# ESP32-C2 register map
Vendor: ESPRESSIF SYSTEMS (SHANGHAI) CO., LTD.; Series: ESP32 C-Series; File version: 11
CPU: RV32IMC r0p0, little endian, no MPU, no FPU, 0 interrupt priority bits
Address unit: 32 bits
Registers are 32-bit, read-write, reset 0x0 unless marked. A register's access mark holds for its fields unless they carry their own. Offsets are from the block's base; [hi:lo] are bit positions; {n}, {i} and the like mark numbered series.

## EFUSE — eFuse Controller
Base 0x60008800
0x00 PGM_DATA0 — Register 0 that stores data to be programmed.
  [31:0] PGM_DATA_0 — The content of the 0th 32-bit data to be programmed.
0x04 PGM_DATA1 — Register 1 that stores data to be programmed.
  [31:0] PGM_DATA_1 — The content of the 1st 32-bit data to be programmed.
0x08 PGM_DATA2 — Register 2 that stores data to be programmed.
  [31:0] PGM_DATA_2 — The content of the 2nd 32-bit data to be programmed.
0x0C PGM_DATA3 — Register 3 that stores data to be programmed.
  [31:0] PGM_DATA_3 — The content of the 3rd 32-bit data to be programmed.
{0x0+4i} PGM_DATA{i} (i=4..7) — Register {i} that stores data to be programmed.
  [31:0] PGM_DATA_{i} — The content of the {i}th 32-bit data to be programmed.
0x20 PGM_CHECK_VALUE0 — Register 0 that stores the RS code to be programmed.
  [31:0] PGM_RS_DATA_0 — The content of the 0th 32-bit RS code to be programmed.
0x24 PGM_CHECK_VALUE1 — Register 1 that stores the RS code to be programmed.
  [31:0] PGM_RS_DATA_1 — The content of the 1st 32-bit RS code to be programmed.
0x28 PGM_CHECK_VALUE2 — Register 2 that stores the RS code to be programmed.
  [31:0] PGM_RS_DATA_2 — The content of the 2nd 32-bit RS code to be programmed.
0x2C RD_WR_DIS ro — BLOCK0 data register 0.
  [7:0] WR_DIS — Disable programming of individual eFuses.
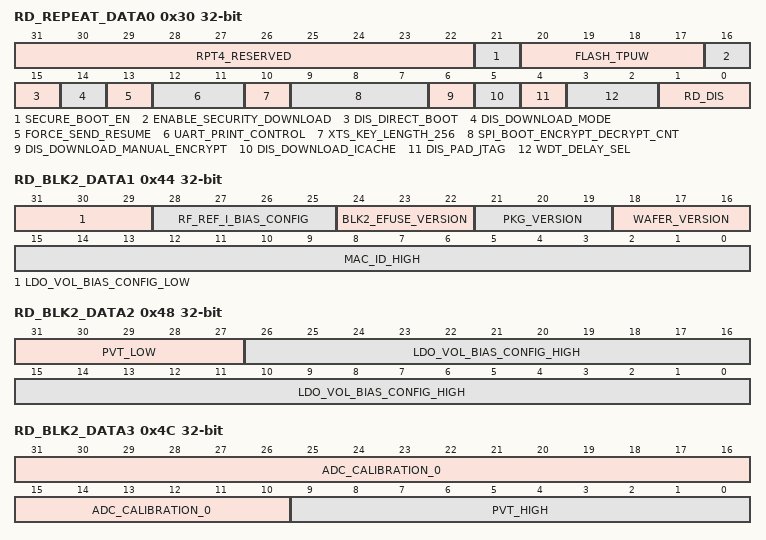
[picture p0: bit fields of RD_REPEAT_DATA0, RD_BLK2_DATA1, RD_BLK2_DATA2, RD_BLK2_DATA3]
0x30 RD_REPEAT_DATA0 ro — BLOCK0 data register 1.
  [31:22] RPT4_RESERVED — Reserved (used for four backups method).
  [21] SECURE_BOOT_EN — The bit be set to enable secure boot.
  [20:17] FLASH_TPUW — Configures flash waiting time after power-up, in unit of ms. If the value is less than 15, the waiting time is the configurable value. Otherwise, the waiting time is twice the configurable value.
  [16] ENABLE_SECURITY_DOWNLOAD — Set this bit to enable secure UART download mode.
  [15] DIS_DIRECT_BOOT — This bit set means disable direct_boot mode.
  [14] DIS_DOWNLOAD_MODE — Set this bit to disable download mode (boot_mode[3:0] = 0, 1, 2, 4, 5, 6, 7).
  [13] FORCE_SEND_RESUME — Set this bit to force ROM code to send a resume command during SPI boot.
  [12:11] UART_PRINT_CONTROL — Set this bit to disable usb printing.
  [10] XTS_KEY_LENGTH_256 — The bit be set means XTS_AES use the whole 256-bit efuse data in BLOCK3. Otherwise, XTS_AES use 128-bit eFuse data in BLOCK3.
  [9:7] SPI_BOOT_ENCRYPT_DECRYPT_CNT — These bits be set to enable SPI boot encrypt/decrypt. Odd number of 1: enable. even number of 1: disable.
  [6] DIS_DOWNLOAD_MANUAL_ENCRYPT — The bit be set to disable manual encryption.
  [5] DIS_DOWNLOAD_ICACHE — The bit be set to disable icache in download mode.
  [4] DIS_PAD_JTAG — Set this bit to disable pad jtag.
  [3:2] WDT_DELAY_SEL — Selects RTC watchdog timeout threshold, in unit of slow clock cycle. 0: 40000. 1: 80000. 2: 160000. 3:320000.
  [1:0] RD_DIS — The bit be set to disable software read high/low 128-bit of BLK3.
0x34 RD_BLK1_DATA0 ro — BLOCK1 data register 0.
  [31:0] SYSTEM_DATA0 — Stores the bits [0:31] of system data.
0x38 RD_BLK1_DATA1 ro — BLOCK1 data register 1.
  [31:0] SYSTEM_DATA1 — Stores the bits [32:63] of system data.
0x3C RD_BLK1_DATA2 ro — BLOCK1 data register 2.
  [23:0] SYSTEM_DATA2 — Stores the bits [64:87] of system data.
0x40 RD_BLK2_DATA0 ro — Register 0 of BLOCK2.
  [31:0] BLK2_DATA0 — Store the bit [0:31] of MAC.
0x44 RD_BLK2_DATA1 ro — Register 1 of BLOCK2.
  [31:29] LDO_VOL_BIAS_CONFIG_LOW — Store the bit [0:2] of ido configuration parameters.
  [28:25] RF_REF_I_BIAS_CONFIG — Store rf configuration parameters.
  [24:22] BLK2_EFUSE_VERSION — Store efuse version.
  [21:19] PKG_VERSION — Store package version.
  [18:16] WAFER_VERSION — Store wafer version.
  [15:0] MAC_ID_HIGH — Store the bit [31:47] of MAC.
0x48 RD_BLK2_DATA2 ro — Register 2 of BLOCK2.
  [31:27] PVT_LOW — Store the bit [0:4] of pvt.
  [26:0] LDO_VOL_BIAS_CONFIG_HIGH — Store the bit [3:29] of ido configuration parameters.
0x4C RD_BLK2_DATA3 ro — Register 3 of BLOCK2.
  [31:10] ADC_CALIBRATION_0 — Store the bit [0:21] of ADC calibration data.
  [9:0] PVT_HIGH — Store the bit [5:14] of pvt.
0x50 RD_BLK2_DATA4 ro — Register 4 of BLOCK2.
  [31:0] ADC_CALIBRATION_1 — Store the bit [22:53] of ADC calibration data.
0x54 RD_BLK2_DATA5 ro — Register 5 of BLOCK2.
  [31:0] ADC_CALIBRATION_2 — Store the bit [54:85] of ADC calibration data.
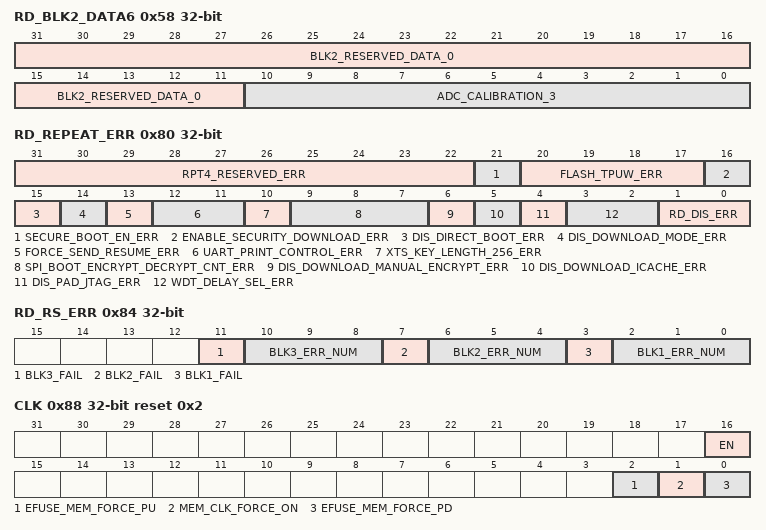
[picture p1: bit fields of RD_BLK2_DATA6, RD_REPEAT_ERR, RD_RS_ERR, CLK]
0x58 RD_BLK2_DATA6 ro — Register 6 of BLOCK2.
  [31:11] BLK2_RESERVED_DATA_0 — Store the bit [0:20] of block2 reserved data.
  [10:0] ADC_CALIBRATION_3 — Store the bit [86:96] of ADC calibration data.
0x5C RD_BLK2_DATA7 ro — Register 7 of BLOCK2.
  [31:0] BLK2_RESERVED_DATA_1 — Store the bit [21:52] of block2 reserved data.
0x60 RD_BLK3_DATA0 ro — Register 0 of BLOCK3.
  [31:0] BLK3_DATA0 — Store the first 32-bit of Block3.
0x64 RD_BLK3_DATA1 ro — Register 1 of BLOCK3.
  [31:0] BLK3_DATA1 — Store the second 32-bit of Block3.
0x68 RD_BLK3_DATA2 ro — Register 2 of BLOCK3.
  [31:0] BLK3_DATA2 — Store the third 32-bit of Block3.
0x6C RD_BLK3_DATA3 ro — Register 3 of BLOCK3.
  [31:0] BLK3_DATA3 — Store the fourth 32-bit of Block3.
0x70 RD_BLK3_DATA4 ro — Register 4 of BLOCK3.
  [31:0] BLK3_DATA4 — Store the fifth 32-bit of Block3.
0x74 RD_BLK3_DATA5 ro — Register 5 of BLOCK3.
  [31:0] BLK3_DATA5 — Store the sixth 32-bit of Block3.
0x78 RD_BLK3_DATA6 ro — Register 6 of BLOCK3.
  [31:0] BLK3_DATA6 — Store the seventh 32-bit of Block3.
0x7C RD_BLK3_DATA7 ro — Register 7 of BLOCK3.
  [31:0] BLK3_DATA7 — Store the eighth 32-bit of Block3.
0x80 RD_REPEAT_ERR ro — Programming error record register 0 of BLOCK0.
  [31:22] RPT4_RESERVED_ERR — Reserved.
  [21] SECURE_BOOT_EN_ERR — If any bit in this filed is 1, then it indicates a programming error.
  [20:17] FLASH_TPUW_ERR — If any bit in this filed is 1, then it indicates a programming error.
  [16] ENABLE_SECURITY_DOWNLOAD_ERR — If any bit in this filed is 1, then it indicates a programming error.
  [15] DIS_DIRECT_BOOT_ERR — If any bit in this filed is 1, then it indicates a programming error.
  [14] DIS_DOWNLOAD_MODE_ERR — If any bit in this filed is 1, then it indicates a programming error.
  [13] FORCE_SEND_RESUME_ERR — If any bit in FORCE_SEND_RESUME is 1, then it indicates a programming error.
  [12:11] UART_PRINT_CONTROL_ERR — If any bit in UART_PRINT_CONTROL is 1, then it indicates a programming error.
  [10] XTS_KEY_LENGTH_256_ERR — If any bit in XTS_KEY_LENGTH_256 is 1, then it indicates a programming error.
  [9:7] SPI_BOOT_ENCRYPT_DECRYPT_CNT_ERR — If any bit in SPI_BOOT_ENCRYPT_DECRYPT_CNT is 1, then it indicates a programming error.
  [6] DIS_DOWNLOAD_MANUAL_ENCRYPT_ERR — If any bit in DIS_DOWNLOAD_MANUAL_ENCRYPT is 1, then it indicates a programming error.
  [5] DIS_DOWNLOAD_ICACHE_ERR — If any bit in this filed is 1, then it indicates a programming error.
  [4] DIS_PAD_JTAG_ERR — If any bit in DIS_PAD_JTAG is 1, then it indicates a programming error.
  [3:2] WDT_DELAY_SEL_ERR — If any bit in WDT_DELAY_SEL is 1, then it indicates a programming error.
  [1:0] RD_DIS_ERR — If any bit in RD_DIS is 1, then it indicates a programming error.
0x84 RD_RS_ERR ro — Programming error record register 0 of BLOCK1-10.
  [11] BLK3_FAIL — 0: Means no failure and that the block3 data is reliable 1: Means that programming user data failed and the number of error bytes is over 6.
  [10:8] BLK3_ERR_NUM — The value of this signal means the number of error bytes in block3.
  [7] BLK2_FAIL — 0: Means no failure and that the data of block2 is reliable 1: Means that programming user data failed and the number of error bytes is over 6.
  [6:4] BLK2_ERR_NUM — The value of this signal means the number of error bytes in block2.
  [3] BLK1_FAIL — 0: Means no failure and that the data of block1 is reliable 1: Means that programming user data failed and the number of error bytes is over 6.
  [2:0] BLK1_ERR_NUM — The value of this signal means the number of error bytes in block1.
0x88 CLK reset 0x2 — eFuse clcok configuration register.
  [16] EN — Set this bit and force to enable clock signal of eFuse memory.
  [2] EFUSE_MEM_FORCE_PU — Set this bit to force eFuse SRAM into working mode.
  [1] MEM_CLK_FORCE_ON — Set this bit and force to activate clock signal of eFuse SRAM.
  [0] EFUSE_MEM_FORCE_PD — Set this bit to force eFuse SRAM into power-saving mode.
0x8C CONF — eFuse operation mode configuraiton register
  [15:0] OP_CODE — 0x5A5A: Operate programming command 0x5AA5: Operate read command.
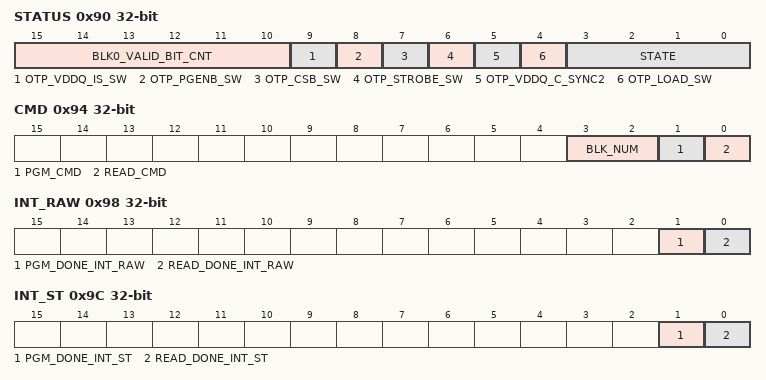
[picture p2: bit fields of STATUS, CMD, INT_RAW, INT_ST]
0x90 STATUS ro — eFuse status register.
  [15:10] BLK0_VALID_BIT_CNT — Record the number of bit '1' in BLOCK0.
  [9] OTP_VDDQ_IS_SW — The value of OTP_VDDQ_IS_SW.
  [8] OTP_PGENB_SW — The value of OTP_PGENB_SW.
  [7] OTP_CSB_SW — The value of OTP_CSB_SW.
  [6] OTP_STROBE_SW — The value of OTP_STROBE_SW.
  [5] OTP_VDDQ_C_SYNC2 — The value of OTP_VDDQ_C_SYNC2.
  [4] OTP_LOAD_SW — The value of OTP_LOAD_SW.
  [3:0] STATE — Indicates the state of the eFuse state machine.
0x94 CMD — eFuse command register.
  [3:2] BLK_NUM — The serial number of the block to be programmed. Value 0-3 corresponds to block number 0-3, respectively.
  [1] PGM_CMD — Set this bit to send programming command.
  [0] READ_CMD — Set this bit to send read command.
0x98 INT_RAW — eFuse raw interrupt register.
  [1] PGM_DONE_INT_RAW — The raw bit signal for pgm_done interrupt.
  [0] READ_DONE_INT_RAW — The raw bit signal for read_done interrupt.
0x9C INT_ST ro — eFuse interrupt status register.
  [1] PGM_DONE_INT_ST — The status signal for pgm_done interrupt.
  [0] READ_DONE_INT_ST — The status signal for read_done interrupt.
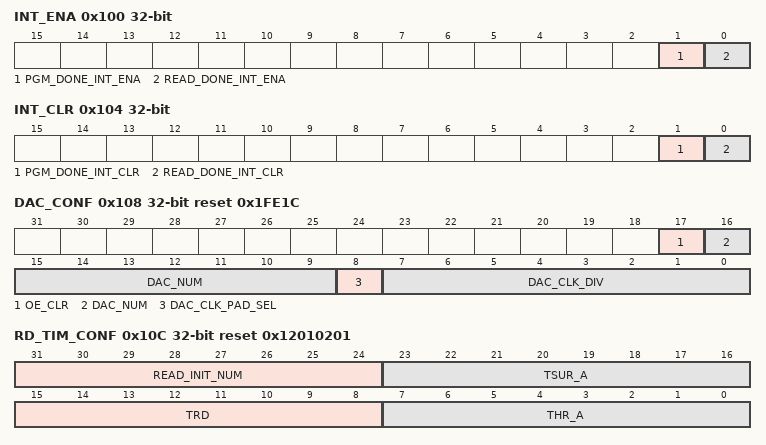
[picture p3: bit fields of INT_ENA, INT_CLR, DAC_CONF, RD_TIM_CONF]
0x100 INT_ENA — eFuse interrupt enable register.
  [1] PGM_DONE_INT_ENA — The enable signal for pgm_done interrupt.
  [0] READ_DONE_INT_ENA — The enable signal for read_done interrupt.
0x104 INT_CLR wo — eFuse interrupt clear register.
  [1] PGM_DONE_INT_CLR — The clear signal for pgm_done interrupt.
  [0] READ_DONE_INT_CLR — The clear signal for read_done interrupt.
0x108 DAC_CONF reset 0x1FE1C — Controls the eFuse programming voltage.
  [17] OE_CLR — Reduces the power supply of the programming voltage.
  [16:9] DAC_NUM — Controls the rising period of the programming voltage.
  [8] DAC_CLK_PAD_SEL — Don't care.
  [7:0] DAC_CLK_DIV — Controls the division factor of the rising clock of the programming voltage.
0x10C RD_TIM_CONF reset 0x12010201 — Configures read timing parameters.
  [31:24] READ_INIT_NUM — Configures the initial read time of eFuse.
  [23:16] TSUR_A — Configures setup time for efuse read.
  [15:8] TRD — Configures pulse time for efuse read.
  [7:0] THR_A — Configures hold time for efuse read.
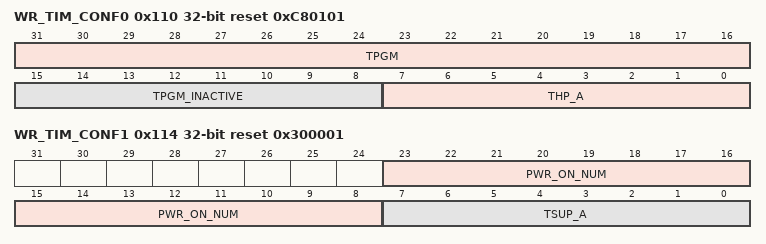
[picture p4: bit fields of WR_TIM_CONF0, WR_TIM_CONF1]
0x110 WR_TIM_CONF0 reset 0xC80101 — Configurarion register 0 of eFuse programming timing parameters.
  [31:16] TPGM — Configures pulse time for burning '1' bit.
  [15:8] TPGM_INACTIVE — Configures pulse time for burning '0' bit.
  [7:0] THP_A — Configures hold time for efuse program.
0x114 WR_TIM_CONF1 reset 0x300001 — Configurarion register 1 of eFuse programming timing parameters.
  [23:8] PWR_ON_NUM — Configures the power up time for VDDQ.
  [7:0] TSUP_A — Configures setup time for efuse program.
0x118 WR_TIM_CONF2 reset 0x190 — Configurarion register 2 of eFuse programming timing parameters.
  [15:0] PWR_OFF_NUM — Configures the power outage time for VDDQ.
0x1FC DATE reset 0x2108190 — eFuse version register.
  [27:0] DATE — Stores eFuse version.
